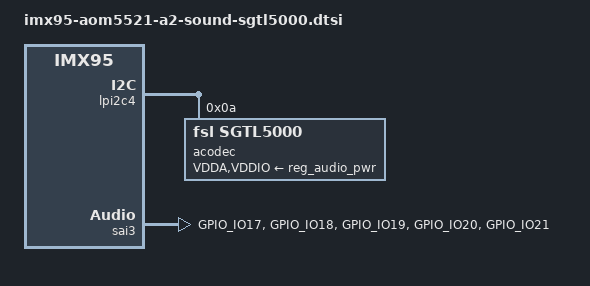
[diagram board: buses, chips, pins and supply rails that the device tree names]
/ {
	sound: sound {
		compatible = "fsl,imx-audio-sgtl5000";
		model = "sgtl5000";
		ssi-controller = <&sai3>;
		audio-codec = <&acodec>;
		no-audmux;
		audio-routing =
			"MIC_IN", "Mic Jack",
			"Mic Jack", "Mic Bias",
			"Headphone Jack", "HP_OUT";
	};
};

&lpi2c4 {
	acodec: sgtl5000@a {
		compatible = "fsl,sgtl5000";
		reg = <0x0a>;
		clocks = <&scmi_clk IMX95_CLK_SAI3>;
		clock-names = "mclk";
		pinctrl-names = "default";
		VDDA-supply = <&reg_audio_pwr>;
		VDDIO-supply = <&reg_audio_pwr>;
	};
};

&sai3 {
	pinctrl-names = "default";
	pinctrl-0 = <&pinctrl_sai3>;
	fsl,sai-synchronous-rx;
};

&scmi_iomuxc {
	pinctrl_sai3: sai3grp {
		fsl,pins = <
			IMX95_PAD_GPIO_IO17__SAI3_MCLK			0x31e
			IMX95_PAD_GPIO_IO18__SAI3_RX_BCLK		0x31e
			IMX95_PAD_GPIO_IO19__SAI3_RX_SYNC		0x31e
			IMX95_PAD_GPIO_IO20__SAI3_RX_DATA_BIT0		0x31e
			IMX95_PAD_GPIO_IO21__SAI3_TX_DATA_BIT0		0x31e
		>;
	};
};
